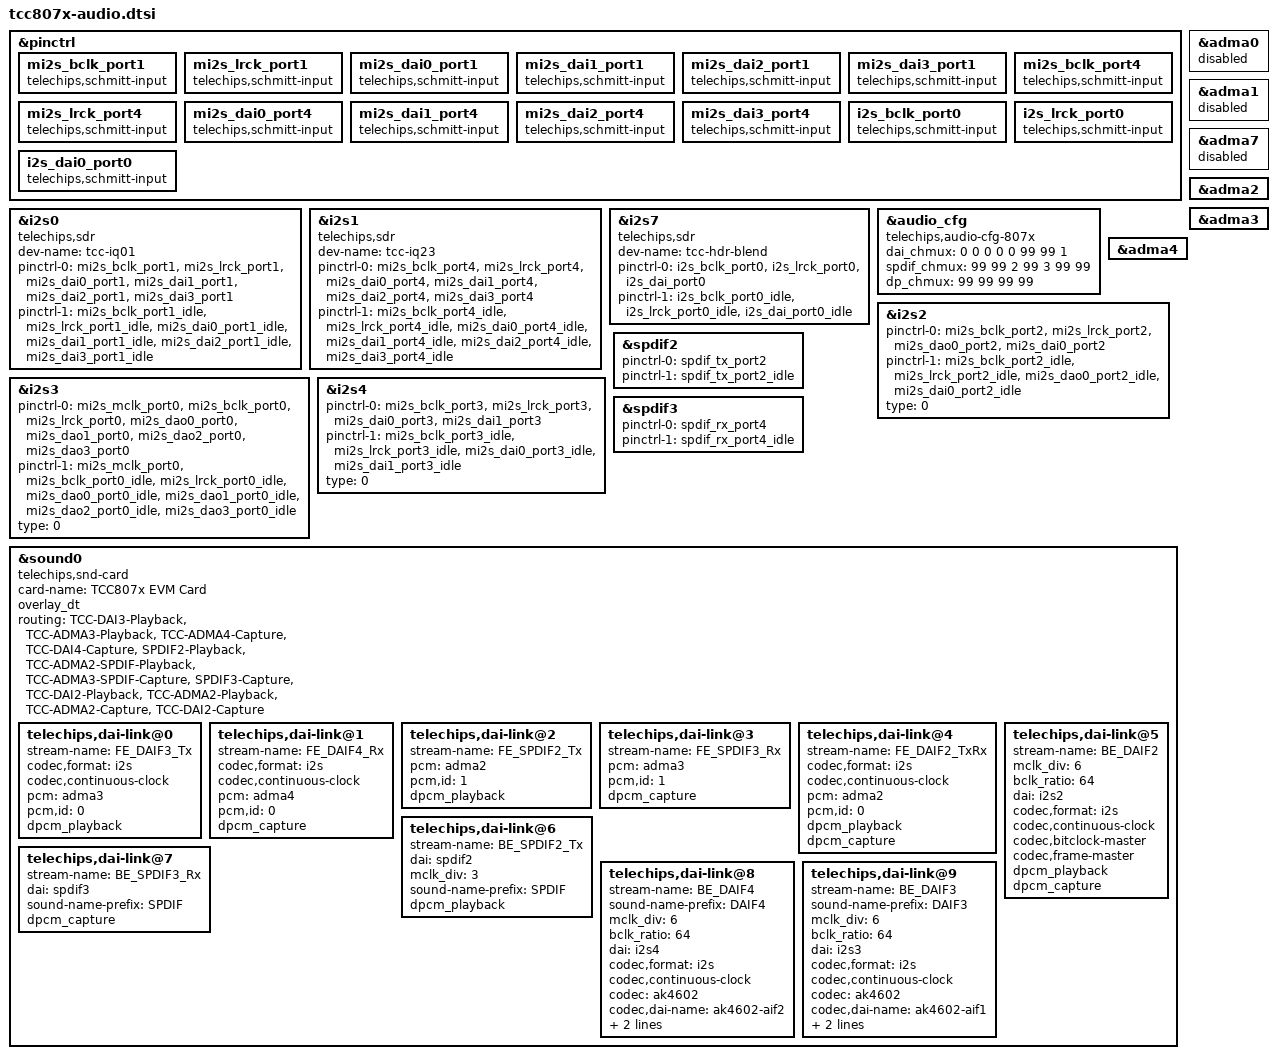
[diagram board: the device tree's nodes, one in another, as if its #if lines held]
&pinctrl {
	mi2s_bclk_port1 {
		telechips,schmitt-input;
	};
	mi2s_lrck_port1 {
		telechips,schmitt-input;
	};
	mi2s_dai0_port1 {
		telechips,schmitt-input;
	};
	mi2s_dai1_port1 {
		telechips,schmitt-input;
	};
	mi2s_dai2_port1 {
		telechips,schmitt-input;
	};
	mi2s_dai3_port1 {
		telechips,schmitt-input;
	};
	mi2s_bclk_port4 {
		telechips,schmitt-input;
	};
	mi2s_lrck_port4 {
		telechips,schmitt-input;
	};
	mi2s_dai0_port4 {
		telechips,schmitt-input;
	};
	mi2s_dai1_port4 {
		telechips,schmitt-input;
	};
	mi2s_dai2_port4 {
		telechips,schmitt-input;
	};
	mi2s_dai3_port4 {
		telechips,schmitt-input;
	};
	i2s_bclk_port0 {
		telechips,schmitt-input;
	};
	i2s_lrck_port0 {
		telechips,schmitt-input;
	};
	i2s_dai0_port0 {
		telechips,schmitt-input;
	};
};

&i2s0 {
	compatible = "telechips,sdr";
	dev-name = "tcc-iq01";
	pinctrl-names = "default", "idle";
	pinctrl-0 = <&mi2s_bclk_port1 &mi2s_lrck_port1
				&mi2s_dai0_port1 &mi2s_dai1_port1
				&mi2s_dai2_port1 &mi2s_dai3_port1>;
	pinctrl-1 = <&mi2s_bclk_port1_idle &mi2s_lrck_port1_idle
				&mi2s_dai0_port1_idle &mi2s_dai1_port1_idle
				&mi2s_dai2_port1_idle &mi2s_dai3_port1_idle>;
	status = "okay";

};

&i2s1 {
	compatible = "telechips,sdr";
	dev-name = "tcc-iq23";
	pinctrl-names = "default", "idle";
	pinctrl-0 = <&mi2s_bclk_port4 &mi2s_lrck_port4
				&mi2s_dai0_port4 &mi2s_dai1_port4
				&mi2s_dai2_port4 &mi2s_dai3_port4>;
	pinctrl-1 = <&mi2s_bclk_port4_idle &mi2s_lrck_port4_idle
				&mi2s_dai0_port4_idle &mi2s_dai1_port4_idle
				&mi2s_dai2_port4_idle &mi2s_dai3_port4_idle>;
	status = "okay";

};

&i2s7 {
	compatible = "telechips,sdr";
	dev-name = "tcc-hdr-blend";
	pinctrl-names = "default", "idle";
	pinctrl-0 = <&i2s_bclk_port0 &i2s_lrck_port0
				&i2s_dai_port0>;
	pinctrl-1 = <&i2s_bclk_port0_idle &i2s_lrck_port0_idle
				&i2s_dai_port0_idle>;
	status = "okay";

};

&adma0 { //for SDR
	status = "disabled";
};

&adma1 { //for SDR
	status = "disabled";
};

&adma7 { //for SDR
	status = "disabled";
};

&audio_cfg{
	compatible = "telechips,audio-cfg-807x";
	dai_chmux = <0 0 0 0 0 99 99 1>;
		// i2s0(GPIO C ) - 0: MI2S(01), 1: I2S(00)
		// i2s1(GPIO MB) - 0: MI2S(04)
		// i2s2(GPIO G ) - 0: MI2S(02), 1: SI2S(01), 2: SI2S(02)
		// i2s3(GPIO A ) - 0: MI2S(00)
		// i2s4(GPIO E ) - 0: MI2S(03), 1: SI2S(03)
		// i2s5(GPIO E ) - 0: SI2S(04)
		// i2s6(GPIO E ) - 0: SI2S(05)
		// i2s7(GPIO C ) - 0: MI2S(01), 1: I2S(00)
		// Prioty: I2S0 > I2S7
	spdif_chmux = <99 99 2 99 3 99 99>;
		/* spdif_port0(x) spdif_port1(x) spdif_port2(4) spdif_port3(5)
			spdif_port4(x) spdif_port5(x) spdif_port6(x) */
	dp_chmux = <99 99 99 99>;
		// dp_port0(x) dp_port1(x) dp_port2(x) dp_port3(x)
	status = "okay";
};

&adma2 { //TEST I2S, SPDIF Tx
	status = "okay";
};

&adma3 { //DAIF Tx, SPDIF Rx
	/* only for PV Test. Don't update main git
	memory-region = <&test_mem>; */
	status = "okay";
};

&adma4 { //DAIF RX
	status = "okay";
};

&i2s2 {	//TEST I2S
	pinctrl-names = "default", "idle";
	pinctrl-0 = <&mi2s_bclk_port2 &mi2s_lrck_port2
				&mi2s_dao0_port2 &mi2s_dai0_port2>;
	pinctrl-1 = <&mi2s_bclk_port2_idle &mi2s_lrck_port2_idle
				&mi2s_dao0_port2_idle &mi2s_dai0_port2_idle>;
	type = <0>; /* 0: adma, 1: fifo(MAFC) */
	status = "okay";

};

&i2s3 {	//DAIF Tx
	pinctrl-names = "default", "idle";
	pinctrl-0 = <&mi2s_mclk_port0 &mi2s_bclk_port0 &mi2s_lrck_port0
				&mi2s_dao0_port0 &mi2s_dao1_port0
				&mi2s_dao2_port0 &mi2s_dao3_port0>;
	pinctrl-1 = <&mi2s_mclk_port0 &mi2s_bclk_port0_idle &mi2s_lrck_port0_idle
				&mi2s_dao0_port0_idle &mi2s_dao1_port0_idle
				&mi2s_dao2_port0_idle &mi2s_dao3_port0_idle>;
	type = <0>; /* 0: adma, 1: fifo(MAFC) */
	status = "okay";
};

&i2s4 {	//DAIF RX
	pinctrl-names = "default", "idle";
	pinctrl-0 = <&mi2s_bclk_port3 &mi2s_lrck_port3
				&mi2s_dai0_port3 &mi2s_dai1_port3>;
	pinctrl-1 = <&mi2s_bclk_port3_idle &mi2s_lrck_port3_idle
				&mi2s_dai0_port3_idle &mi2s_dai1_port3_idle>;
	type = <0>; /* 0: adma, 1: fifo(MAFC) */
	status = "okay";
};

&spdif2 {
	pinctrl-names = "default", "idle";
	pinctrl-0 = <&spdif_tx_port2>;
	pinctrl-1 = <&spdif_tx_port2_idle>;
	status = "okay";
};

&spdif3 {
	pinctrl-names = "default", "idle";
	pinctrl-0 = <&spdif_rx_port4>;
	pinctrl-1 = <&spdif_rx_port4_idle>;
	status = "okay";
};

#if 0
&dptx_audio {
	audio-input = <2 2 2 2>;
	data-width = <16 16 16 16>;
	channels = <2 2 2 2>;
	clock-frequency = <32000 32000 32000 32000>;
	status = "disabled";
};
#endif

&sound0 {
	compatible = "telechips,snd-card";
	card-name = "TCC807x EVM Card";
	status = "okay";
#ifdef DT_OVERLAY
	overlay_dt;
#endif
	routing = "TCC-DAI3-Playback", "TCC-ADMA3-Playback",
			"TCC-ADMA4-Capture", "TCC-DAI4-Capture",
			"SPDIF2-Playback", "TCC-ADMA2-SPDIF-Playback",
			"TCC-ADMA3-SPDIF-Capture", "SPDIF3-Capture",
			"TCC-DAI2-Playback", "TCC-ADMA2-Playback",
			"TCC-ADMA2-Capture", "TCC-DAI2-Capture";

	telechips,dai-link@0 {
		stream-name="FE_DAIF3_Tx";
		codec,format = "i2s";
		codec,continuous-clock;
		pcm = <&adma3>;
		pcm,id = <0>; //dai tx
		dpcm_playback;
	};

	telechips,dai-link@1 {
		stream-name="FE_DAIF4_Rx";
		codec,format = "i2s";
		codec,continuous-clock;
		pcm = <&adma4>;
		pcm,id = <0>; //dai rx
		dpcm_capture;
	};

	telechips,dai-link@2 {
		stream-name="FE_SPDIF2_Tx";
		pcm = <&adma2>;
		pcm,id = <1>; //spdif tx
		dpcm_playback;
	};

	telechips,dai-link@3 {
		stream-name="FE_SPDIF3_Rx";
		pcm = <&adma3>;
		pcm,id = <1>; //spdif rx
		dpcm_capture;
	};

	telechips,dai-link@4 {
		stream-name="FE_DAIF2_TxRx";
		codec,format = "i2s";
		codec,continuous-clock;
		pcm = <&adma2>;
		pcm,id = <0>; //dai tx,rx
		dpcm_playback;
		dpcm_capture;
	};

	telechips,dai-link@5 {
		stream-name="BE_DAIF2";
		mclk_div = <6>;
		bclk_ratio = <64>; // 32,48,64fs
		dai = <&i2s2>;
		codec,format = "i2s";
		codec,continuous-clock;
		codec,bitclock-master;
		codec,frame-master;
		dpcm_playback;
		dpcm_capture;
	};

	telechips,dai-link@6 {
		stream-name="BE_SPDIF2_Tx";
		dai = <&spdif2>;
		mclk_div = <3>;
		sound-name-prefix = "SPDIF";
		dpcm_playback;
	};

	telechips,dai-link@7 {
		stream-name="BE_SPDIF3_Rx";
		dai = <&spdif3>;
		sound-name-prefix = "SPDIF";
		dpcm_capture;
	};

	telechips,dai-link@8 {
		stream-name="BE_DAIF4";
		sound-name-prefix = "DAIF4";
		mclk_div = <6>;
		bclk_ratio = <64>; // 32,48,64fs
		dai = <&i2s4>;
		codec,format = "i2s";
		codec,continuous-clock;
		codec = <&ak4602>;
		codec,dai-name = "ak4602-aif2";
		dpcm_playback;
		dpcm_capture;
	};

	telechips,dai-link@9 {
		stream-name="BE_DAIF3";
		sound-name-prefix = "DAIF3";
		mclk_div = <6>;
		bclk_ratio = <64>; // 32,48,64fs
		dai = <&i2s3>;
		codec,format = "i2s";
		codec,continuous-clock;
		codec = <&ak4602>;
		codec,dai-name = "ak4602-aif1";
		dpcm_playback;
		dpcm_capture;

	};
};
